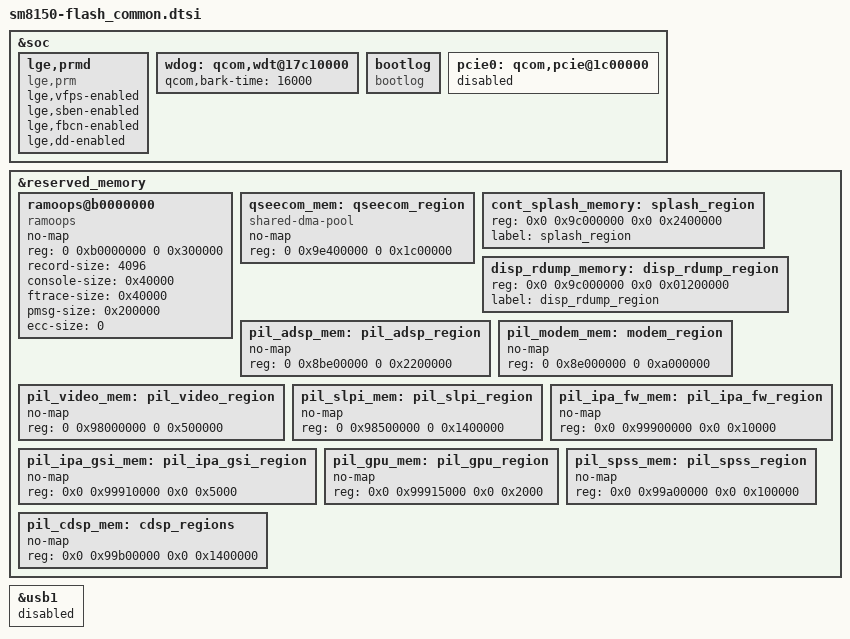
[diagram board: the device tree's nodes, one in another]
/*
 * Copyright (c) 2018, The Linux Foundation. All rights reserved.
 *
 * This program is free software; you can redistribute it and/or modify
 * it under the terms of the GNU General Public License version 2 and
 * only version 2 as published by the Free Software Foundation.
 *
 * This program is distributed in the hope that it will be useful,
 * but WITHOUT ANY WARRANTY; without even the implied warranty of
 * MERCHANTABILITY or FITNESS FOR A PARTICULAR PURPOSE.  See the
 * GNU General Public License for more details.
 */


&soc {

	lge,prmd {
		compatible = "lge,prm";
		lge,vfps-enabled;
		lge,sben-enabled;
		lge,fbcn-enabled;
		lge,dd-enabled;
	};

};

&soc {
	wdog: qcom,wdt@17c10000{
		qcom,bark-time = <16000>;
	};

	bootlog {
		compatible = "bootlog";
	};

	pcie0: qcom,pcie@1c00000 {
		status = "disabled";
	};
};

&reserved_memory {
	#address-cells = <2>;
	#size-cells = <2>;

	ramoops@b0000000 {
		compatible = "ramoops";
		no-map;
		reg = <0 0xb0000000 0 0x300000>;
		record-size = <4096>;
		console-size = <0x40000>;
		ftrace-size = <0x40000>;
		pmsg-size = <0x200000>;
		ecc-size = <0>;
	};

	qseecom_mem: qseecom_region {
		compatible = "shared-dma-pool";
		no-map;
		reg = <0 0x9e400000 0 0x1c00000>;
	};

	cont_splash_memory: splash_region {
		reg = <0x0 0x9c000000 0x0 0x2400000>;
		label = "splash_region";
	};

	disp_rdump_memory: disp_rdump_region {
		reg = <0x0 0x9c000000 0x0 0x01200000>;
		label = "disp_rdump_region";
	};

	pil_adsp_mem: pil_adsp_region {
		no-map;
		reg = <0 0x8be00000 0 0x2200000>;
	};

	pil_modem_mem: modem_region {
		no-map;
		reg = <0 0x8e000000 0 0xa000000>;
	};

	pil_video_mem: pil_video_region {
		no-map;
		reg = <0 0x98000000 0 0x500000>;
	};

	pil_slpi_mem: pil_slpi_region {
		no-map;
		reg = <0 0x98500000 0 0x1400000>;
	};

	pil_ipa_fw_mem: pil_ipa_fw_region {
		no-map;
		reg = <0x0 0x99900000 0x0 0x10000>;
	};

	pil_ipa_gsi_mem: pil_ipa_gsi_region {
		no-map;
		reg = <0x0 0x99910000 0x0 0x5000>;
	};

	pil_gpu_mem: pil_gpu_region {
		no-map;
		reg = <0x0 0x99915000 0x0 0x2000>;
	};

	pil_spss_mem: pil_spss_region {
		no-map;
		reg = <0x0 0x99a00000 0x0 0x100000>;
	};

	pil_cdsp_mem: cdsp_regions {
		no-map;
		reg = <0x0 0x99b00000 0x0 0x1400000>;
	};
};

&usb1 {
       status = "disabled";
};

